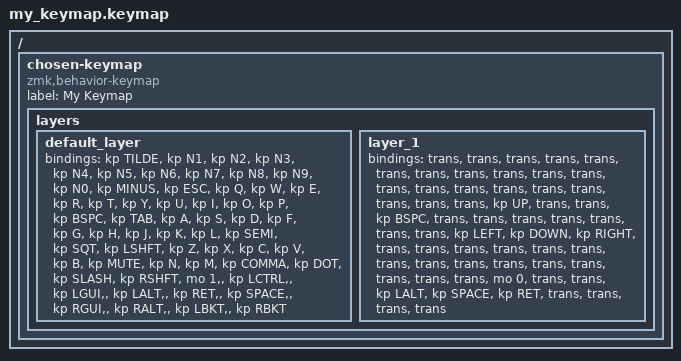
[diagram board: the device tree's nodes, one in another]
/* My Sofle Choc v2 Keymap */

#include <dt-bindings/zmk/keys.h>
#include <dt-bindings/zmk/mouse.h>
#include <dt-bindings/zmk/hid_usage.h>

/ {
    chosen-keymap {
        compatible = "zmk,behavior-keymap";
        label = "My Keymap";
        
        layers {
            default_layer {
                bindings = <
&kp TILDE   &kp N1      &kp N2      &kp N3      &kp N4      &kp N5          &kp N6      &kp N7      &kp N8      &kp N9      &kp N0      &kp MINUS
&kp ESC     &kp Q       &kp W       &kp E       &kp R       &kp T           &kp Y       &kp U       &kp I       &kp O       &kp P       &kp BSPC
&kp TAB     &kp A       &kp S       &kp D       &kp F       &kp G           &kp H       &kp J       &kp K       &kp L       &kp SEMI    &kp SQT
&kp LSHFT   &kp Z       &kp X       &kp C       &kp V       &kp B &kp MUTE  &kp N       &kp M       &kp COMMA   &kp DOT     &kp SLASH   &kp RSHFT
                                &mo 1,      &kp LCTRL,  &kp LGUI,   &kp LALT,   &kp RET,    &kp SPACE,  &kp RGUI,   &kp RALT,   &kp LBKT,   &kp RBKT
                >;
            };
            
            layer_1 {
                bindings = <
&trans      &trans      &trans      &trans      &trans      &trans      &trans      &trans      &trans      &trans      &trans      &trans
&trans      &trans      &trans      &trans      &trans      &trans      &trans      &trans      &kp UP      &trans      &trans      &kp BSPC
&trans      &trans      &trans      &trans      &trans      &trans      &trans      &kp LEFT    &kp DOWN    &kp RIGHT   &trans      &trans
&trans      &trans      &trans      &trans      &trans      &trans &trans &trans   &trans      &trans      &trans      &trans      &trans
                         &mo 0       &trans      &trans      &kp LALT    &kp SPACE   &kp RET     &trans      &trans      &trans      &trans
                >;
            };
        };
    };
};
